# CC1314R10 register map
File version: 1.0
CPU: CM33 1.0, other endian, MPU, FPU, 3 interrupt priority bits
Registers are 32-bit, read-write, reset 0x0 unless marked. A register's access mark holds for its fields unless they carry their own. Offsets are from the block's base; [hi:lo] are bit positions; {n}, {i} and the like mark numbered series.

## AON_RTC — This component control the Real Time Clock residing in AON Note: This module is only supporting 32 bit ReadWrite access.
Base 0x58092000
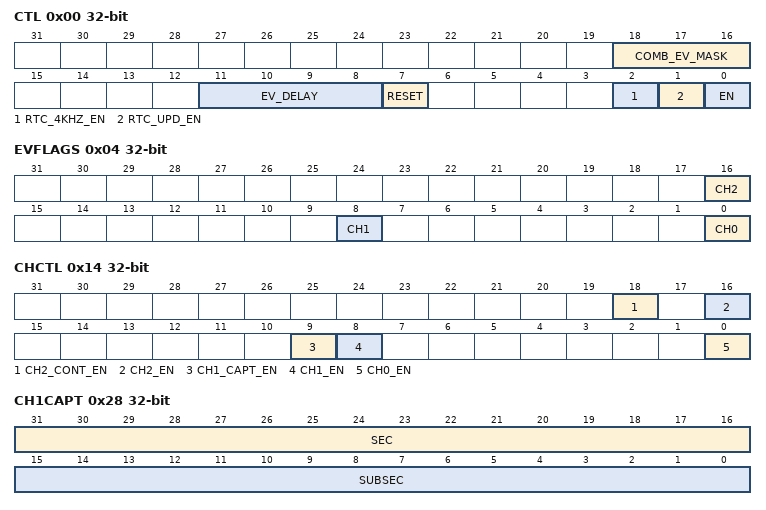
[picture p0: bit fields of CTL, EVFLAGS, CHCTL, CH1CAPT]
0x00 CTL — Control This register contains various bitfields for configuration of RTC RTL Name = CONFIG
  [18:16] COMB_EV_MASK — [18:16] Eventmask selecting which delayed events that form the combined event.
    4=CH2 (Use Channel 2 delayed event in combined event); 2=CH1 (Use Channel 1 delayed event in combined event); 1=CH0 (Use Channel 0 delayed event in combined event); 0=NONE (No event is selected for combined event.)
  [11:8] EV_DELAY — [11:8] Number of SCLK_LF clock cycles waited before generating delayed events. (Common setting for all RTC cannels) the delayed event is delayed
    13=D144 (Delay by 144 clock cycles); 12=D128 (Delay by 128 clock cycles); 11=D112 (Delay by 112 clock cycles); 10=D96 (Delay by 96 clock cycles); 9=D80 (Delay by 80 clock cycles); 8=D64 (Delay by 64 clock cycles); 7=D48 (Delay by 48 clock cycles); 6=D32 (Delay by 32 clock cycles); 5=D16 (Delay by 16 clock cycles); 4=D8 (Delay by 8 clock cycles); 3=D4 (Delay by 4 clock cycles); 2=D2 (Delay by 2 clock cycles); 1=D1 (Delay by 1 clock cycles); 0=D0 (No delay on delayed event)
  [7] RESET wo — [7:7] RTC Counter reset. Writing 1 to this bit will reset the RTC counter. This bit is cleared when reset takes effect
  [2] RTC_4KHZ_EN — [2:2] RTC_4KHZ is a 4 KHz reference output, tapped from SUBSEC.VALUE bit 19 which is used by AUX timer. 0: RTC_4KHZ signal is forced to 0 1: RTC_4KHZ is enabled ( provied that RTC is enabled EN)
  [1] RTC_UPD_EN — [1:1] RTC_UPD is a 16 KHz signal used to sync up the radio timer. The 16 Khz is SCLK_LF divided by 2 0: RTC_UPD signal is forced to 0 1: RTC_UPD signal is toggling @16 kHz
  [0] EN — [0:0] Enable RTC counter 0: Halted (frozen) 1: Running
0x04 EVFLAGS — Event Flags, RTC Status This register contains event flags from the 3 RTC channels. Each flag will be cleared when writing a '1' to the corresponding bitfield.
  [16] CH2 — [16:16] Channel 2 event flag, set when CHCTL.CH2_EN = 1 and the RTC value matches or passes the CH2CMP value. An event will be scheduled to occur as soon as possible when writing to CH2CMP provided that the channel is enabled and the new value matches any time between next RTC value and 1 second in the past Writing 1 clears this flag. AUX_SCE can read the flag through AUX_EVCTL:EVSTAT2.AON_RTC_CH2 and clear it using AUX_SYSIF:RTCEVCLR.RTC_CH2_EV_CLR.
  [8] CH1 — [8:8] Channel 1 event flag, set when CHCTL.CH1_EN = 1 and one of the following: - CHCTL.CH1_CAPT_EN = 0 and the RTC value matches or passes the CH1CMP value. - CHCTL.CH1_CAPT_EN = 1 and capture occurs. An event will be scheduled to occur as soon as possible when writing to CH1CMP provided that the channel is enabled, in compare mode and the new value matches any time between next RTC value and 1 second in the past. Writing 1 clears this flag.
  [0] CH0 — [0:0] Channel 0 event flag, set when CHCTL.CH0_EN = 1 and the RTC value matches or passes the CH0CMP value. An event will be scheduled to occur as soon as possible when writing to CH0CMP provided that the channels is enabled and the new value matches any time between next RTC value and 1 second in the past. Writing 1 clears this flag.
0x08 SEC — Second Counter Value, Integer Part
  [31:0] VALUE — [31:0] Unsigned integer representing Real Time Clock in seconds. When reading this register the content of SUBSEC.VALUE is simultaneously latched. A consistent reading of the combined Real Time Clock can be obtained by first reading this register, then reading SUBSEC register.
0x0C SUBSEC — Second Counter Value, Fractional Part
  [31:0] VALUE — [31:0] Unsigned integer representing Real Time Clock in fractions of a second (VALUE/2^32 seconds) at the time when SEC register was read. Examples : - 0x0000_0000 = 0.0 sec - 0x4000_0000 = 0.25 sec - 0x8000_0000 = 0.5 sec - 0xC000_0000 = 0.75 sec
0x10 SUBSECINC reset 0x800000 — Subseconds Increment Value added to SUBSEC.VALUE on every SCLK_LFclock cycle.
  [23:0] VALUEINC ro — [23:0] This value compensates for a SCLK_LF clock which has an offset from 32768 Hz. The compensation value can be found as 2^38 / freq, where freq is SCLK_LF clock frequency in Hertz This value is added to SUBSEC.VALUE on every cycle, and carry of this is added to SEC.VALUE. To perform the addition, bits [23:6] are aligned with SUBSEC.VALUE bits [17:0]. The remaining bits [5:0] are accumulated in a hidden 6-bit register that generates a carry into the above mentioned addition on overflow. The default value corresponds to incrementing by precisely 1/32768 of a second. NOTE: This register is read only. Modification of the register value must be done using registers AUX_SYSIF:RTCSUBSECINC0 , AUX_SYSIF:RTCSUBSECINC1 and AUX_SYSIF:RTCSUBSECINCCTL
0x14 CHCTL — Channel Configuration
  [18] CH2_CONT_EN — [18:18] Set to enable continuous operation of Channel 2
  [16] CH2_EN — [16:16] RTC Channel 2 Enable 0: Disable RTC Channel 2 1: Enable RTC Channel 2
  [9] CH1_CAPT_EN — [9:9] Set Channel 1 mode 0: Compare mode (default) 1: Capture mode
  [8] CH1_EN — [8:8] RTC Channel 1 Enable 0: Disable RTC Channel 1 1: Enable RTC Channel 1
  [0] CH0_EN — [0:0] RTC Channel 0 Enable 0: Disable RTC Channel 0 1: Enable RTC Channel 0
{0x18+4i} CH{i}CMP (i=0..2) — Channel {i} Compare Value
  [31:0] VALUE — [31:0] RTC Channel {i} compare value. Bit 31 to 16 represents seconds and bits 15 to 0 represents subseconds of the compare value. The compare value is compared against SEC.VALUE (15:0) and SUBSEC.VALUE (31:16) values of the Real Time Clock register. A Cannel 0 event is generated when {SEC.VALUE(15:0),SUBSEC.VALUE (31:16)} is reaching or exciting the compare value. Writing to this register can trigger an immediate*) event in case the new compare value matches a Real Time Clock value from 1 second in the past up till current Real Time Clock value. Example: To generate a compare 5.5 seconds RTC start,- set this value = 0x0005_8000 *) It can take up to one SCLK_LF clock cycles before event occurs due to synchronization.
0x24 CH2CMPINC — Channel 2 Compare Value Auto-increment This register is primarily used to generate periodical wake-up for the AUX_SCE module, through the [AUX_EVCTL.EVSTAT0.AON_RTC] event.
  [31:0] VALUE — [31:0] If CHCTL.CH2_CONT_EN is set, this value is added to CH2CMP.VALUE on every channel 2 compare event.
0x28 CH1CAPT — Channel 1 Capture Value If CHCTL.CH1_EN = 1and CHCTL.CH1_CAPT_EN = 1, capture occurs on each rising edge of the event selected in AON_EVENT:RTCSEL.
  [31:16] SEC ro — [31:16] Value of SEC.VALUE bits 15:0 at capture time.
  [15:0] SUBSEC ro — [15:0] Value of SUBSEC.VALUE bits 31:16 at capture time.
0x2C SYNC — AON Synchronization This register is used for synchronizing between MCU and entire AON domain.
  [0] WBUSY — [0:0] This register will always return 0,- however it will not return the value until there are no outstanding write requests between MCU and AON Note: Writing to this register prior to reading will force a wait until next SCLK_MF edge. This is recommended for syncing read registers from AON when waking up from sleep Failure to do so may result in reading AON values from prior to going to sleep
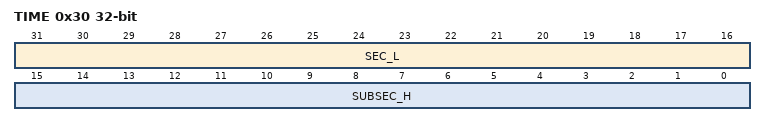
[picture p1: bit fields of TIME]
0x30 TIME — Current Counter Value
  [31:16] SEC_L ro — [31:16] Returns the lower halfword of SEC register.
  [15:0] SUBSEC_H ro — [15:0] Returns the upper halfword of SUBSEC register.
0x34 SYNCLF — Synchronization to SCLK_LF This register is used for synchronizing MCU to positive or negative edge of SCLK_LF.
  [0] PHASE ro — [0:0] This bit will always return the SCLK_LF phase. The return will delayed until a positive or negative edge of SCLK_LF is seen. 0: Falling edge of SCLK_LF 1: Rising edge of SCLK_LF
